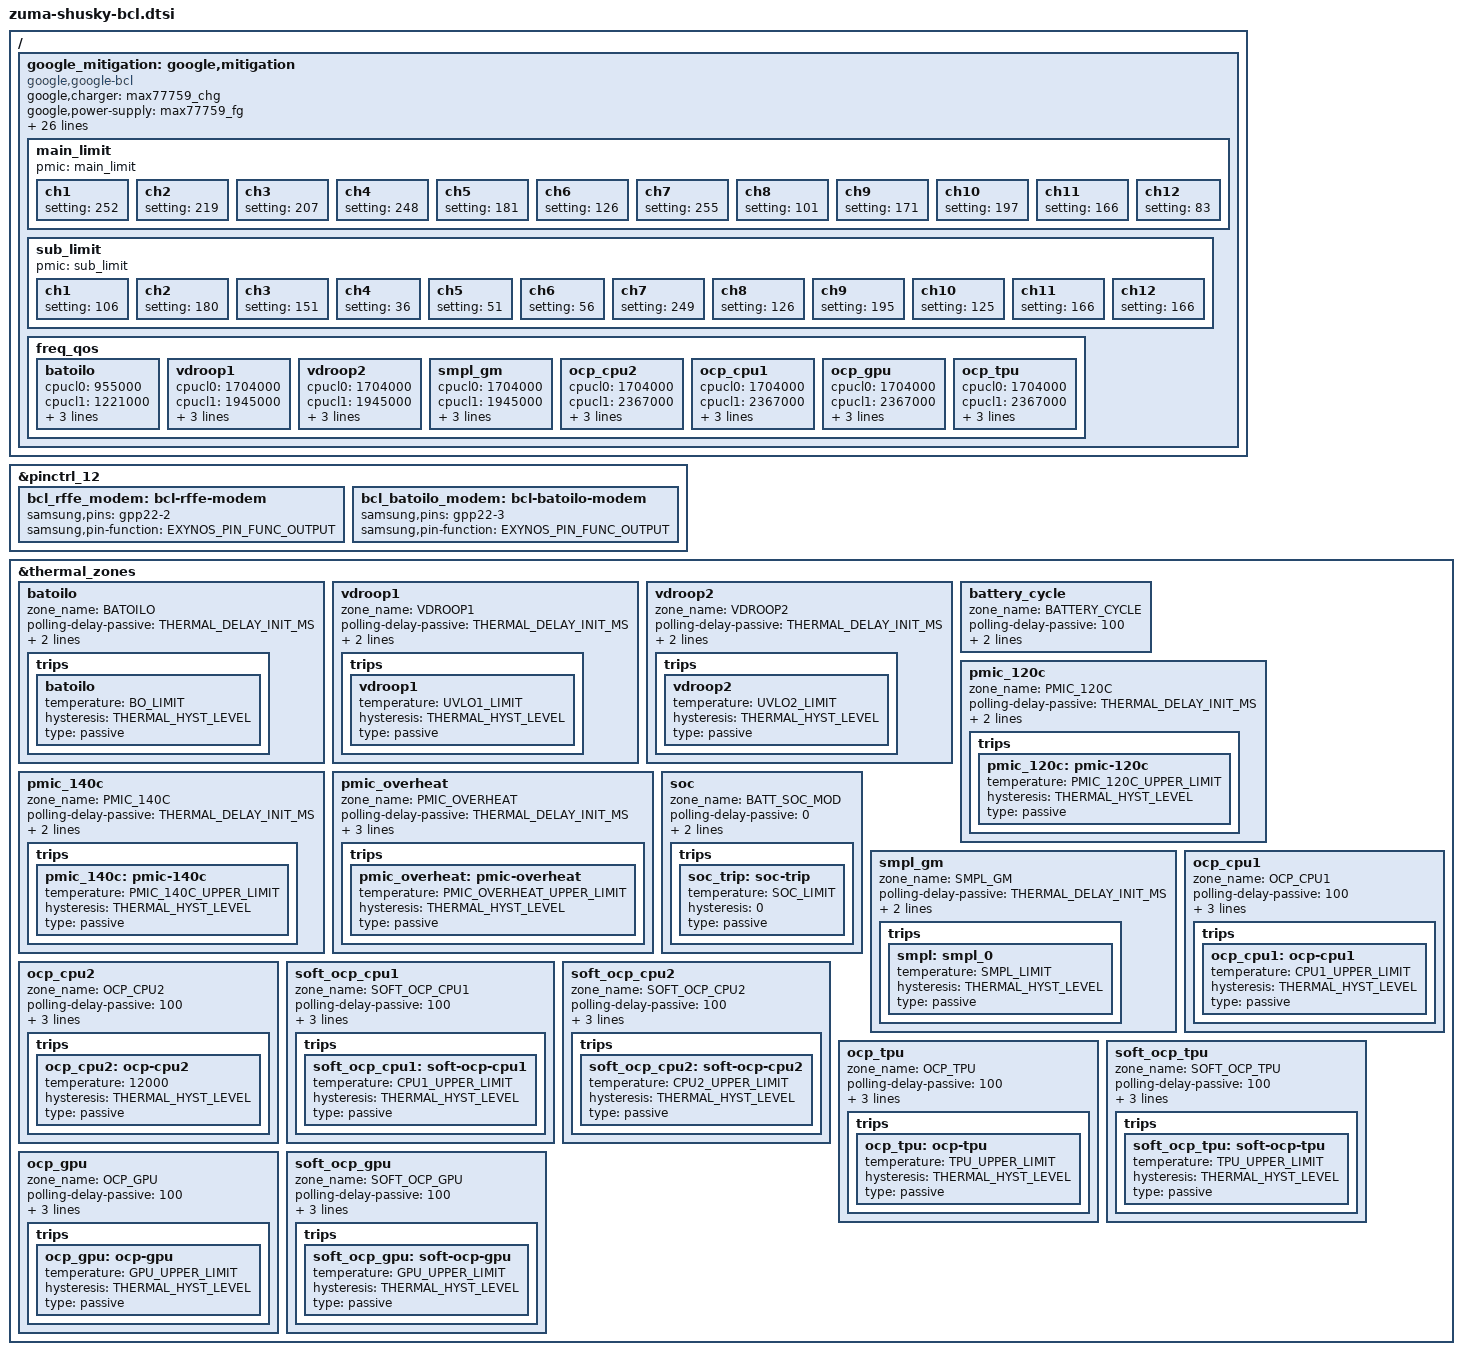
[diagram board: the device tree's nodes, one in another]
// SPDX-License-Identifier: GPL-2.0
/*
 * Google Zuma shusky-specific bcl device tree source
 *
 * Copyright (c) 2022 Google, LLC
 *		https://www.google.com
 */

#include <dt-bindings/thermal/thermal.h>
#include <dt-bindings/soc/google/zuma-bcl.h>

&pinctrl_12 {
	bcl_rffe_modem: bcl-rffe-modem {
		samsung,pins = "gpp22-2";
		samsung,pin-function = <EXYNOS_PIN_FUNC_OUTPUT>;
	};
	bcl_batoilo_modem: bcl-batoilo-modem {
		samsung,pins = "gpp22-3";
		samsung,pin-function = <EXYNOS_PIN_FUNC_OUTPUT>;
	};
};

/ {
	fragment@battery {
		target-path = "/";
		__overlay__ {
			google_mitigation: google,mitigation {
				compatible = "google,google-bcl";
				#thermal-sensor-cells = <1>;
				google,charger = <&max77759_chg>;
				google,power-supply = <&max77759_fg>;
				google,main-power = <&s2mpg14mfd>;
				google,sub-power = <&s2mpg15mfd>;
				ppm_settings = <0>;
				lit_mpmm_settings = <0x1AA>;
				mid_mpmm_settings = <0x1AA>;
				big_mpmm_settings = <0x6>;
				mpmm_en = <0x1f0>;
				tpu_con_heavy = <0xfff041c3>;
				tpu_con_light = <0xfff041c1>;
				tpu_clkdivstep = <0x1>;
				gpu_con_heavy = <0xfff04385>;
				gpu_con_light = <0xfff041c1>;
				gpu_clkdivstep = <0x1>;
				cpu2_clkdivstep = <0x1>;
				cpu1_clkdivstep = <0x1>;
				cpu0_clkdivstep = <0x1>;
				aur_clkdivstep = <0x1>;
				irq_enable_delay = <50>;
				odpm_ratio = <3>;
				gpios = <&gpa9 5 0>,		/* VDROOP1 */
					<&gpa9 6 0>,		/* VDROOP2 */
					<&gpp22 2 0>,		/* MODEM 1 */
					<&gpp22 3 0>;		/* MODEM 2 */
				rffe_channel = <11>;
				pinctrl-names = "bcl-rffe-modem", "bcl-batoilo-modem";
				pinctrl-0 = <&bcl_rffe_modem>;
				pinctrl-1 = <&bcl_batoilo_modem>;
				cpu0_cluster = <0>;
				cpu1_cluster = <4>;
				cpu2_cluster = <8>;

				main_limit {
					pmic = "main_limit";
					ch1 { setting = <252>; };
					ch2 { setting = <219>; };
					ch3 { setting = <207>; };
					ch4 { setting = <248>; };
					ch5 { setting = <181>; };
					ch6 { setting = <126>; };
					ch7 { setting = <255>; };
					ch8 { setting = <101>; };
					ch9 { setting = <171>; };
					ch10 { setting = <197>; };
					ch11 { setting = <166>; };
					ch12 { setting = <83>; };
				};
				sub_limit {
					pmic = "sub_limit";
					ch1 { setting = <106>; };
					ch2 { setting = <180>; };
					ch3 { setting = <151>; };
					ch4 { setting = <36>; };
					ch5 { setting = <51>; };
					ch6 { setting = <56>; };
					ch7 { setting = <249>; };
					ch8 { setting = <126>; };
					ch9 { setting = <195>; };
					ch10 { setting = <125>; };
					ch11 { setting = <166>; };
					ch12 { setting = <166>; };
				};
				freq_qos {
					batoilo {
						cpucl0 = <955000>;
						cpucl1 = <1221000>;
						cpucl2 = <1557000>;
						gpu = <723000>;
						tpu = <845000>;
					};
					vdroop1 {
						cpucl0 = <1704000>;
						cpucl1 = <1945000>;
						cpucl2 = <2294000>;
						gpu = <890000>;
						tpu = <845000>;
					};
					vdroop2 {
						cpucl0 = <1704000>;
						cpucl1 = <1945000>;
						cpucl2 = <2294000>;
						gpu = <649000>;
						tpu = <627000>;
					};
					smpl_gm {
						cpucl0 = <1704000>;
						cpucl1 = <1945000>;
						cpucl2 = <2294000>;
						gpu = <649000>;
						tpu = <627000>;
					};
					ocp_cpu2 {
						cpucl0 = <1704000>;
						cpucl1 = <2367000>;
						cpucl2 = <2914000>;
						gpu = <890000>;
						tpu = <1119000>;
					};
					ocp_cpu1 {
						cpucl0 = <1704000>;
						cpucl1 = <2367000>;
						cpucl2 = <2914000>;
						gpu = <890000>;
						tpu = <1119000>;
					};
					ocp_gpu {
						cpucl0 = <1704000>;
						cpucl1 = <2367000>;
						cpucl2 = <2914000>;
						gpu = <890000>;
						tpu = <1119000>;
					};
					ocp_tpu {
						cpucl0 = <1704000>;
						cpucl1 = <2367000>;
						cpucl2 = <2914000>;
						gpu = <890000>;
						tpu = <1119000>;
					};
				};
			};
		};
	};
};

/* Thermal Zones */
&thermal_zones {
	batoilo {
		zone_name  = "BATOILO";
		polling-delay-passive = <THERMAL_DELAY_INIT_MS>;
		polling-delay = <0>;
		thermal-sensors = <&google_mitigation BATOILO>;
		trips {
			batoilo: batoilo{
				temperature = <BO_LIMIT>;
				hysteresis = <THERMAL_HYST_LEVEL>;
				type = "passive";
			};
		};
	};

	vdroop1 {
		zone_name  = "VDROOP1";
		polling-delay-passive = <THERMAL_DELAY_INIT_MS>;
		polling-delay = <0>;
		thermal-sensors = <&google_mitigation UVLO1>;
		trips {
			vdroop1: vdroop1{
				temperature = <UVLO1_LIMIT>;
				hysteresis = <THERMAL_HYST_LEVEL>;
				type = "passive";
			};
		};
	};

	vdroop2 {
		zone_name  = "VDROOP2";
		polling-delay-passive = <THERMAL_DELAY_INIT_MS>;
		polling-delay = <0>;
		thermal-sensors = <&google_mitigation UVLO2>;
		trips {
			vdroop2: vdroop2{
				temperature = <UVLO2_LIMIT>;
				hysteresis = <THERMAL_HYST_LEVEL>;
				type = "passive";
			};
		};
	};

	battery_cycle {
		zone_name  = "BATTERY_CYCLE";
		polling-delay-passive = <100>;
		polling-delay = <0>;
		thermal-sensors = <&google_battery>;
	};

	pmic_120c {
		zone_name  = "PMIC_120C";
		polling-delay-passive = <THERMAL_DELAY_INIT_MS>;
		polling-delay = <0>;
		thermal-sensors = <&google_mitigation PMIC_120C>;
		trips {
			pmic_120c: pmic-120c {
				temperature = <PMIC_120C_UPPER_LIMIT>;
				hysteresis = <THERMAL_HYST_LEVEL>;
				type = "passive";
			};
		};
	};

	pmic_140c {
		zone_name  = "PMIC_140C";
		polling-delay-passive = <THERMAL_DELAY_INIT_MS>;
		polling-delay = <0>;
		thermal-sensors = <&google_mitigation PMIC_140C>;
		trips {
			pmic_140c: pmic-140c {
				temperature = <PMIC_140C_UPPER_LIMIT>;
				hysteresis = <THERMAL_HYST_LEVEL>;
				type = "passive";
			};
		};
	};

	pmic_overheat {
		zone_name  = "PMIC_OVERHEAT";
		polling-delay-passive = <THERMAL_DELAY_INIT_MS>;
		polling-delay = <0>;
		thermal-sensors = <&google_mitigation PMIC_OVERHEAT>;
		trips {
			pmic_overheat: pmic-overheat{
				temperature = <PMIC_OVERHEAT_UPPER_LIMIT>;
				hysteresis = <THERMAL_HYST_LEVEL>;
				type = "passive";
			};
		};
	};

	soc {
		zone_name  = "BATT_SOC_MOD";
		polling-delay-passive = <0>;
		polling-delay = <0>;
		thermal-sensors = <&google_mitigation PMIC_SOC>;

		trips {
			soc_trip:soc-trip {
				temperature = <SOC_LIMIT>;
				hysteresis = <0>;
				type = "passive";
			};
		};
	};

	smpl_gm {
		zone_name  = "SMPL_GM";
		polling-delay-passive = <THERMAL_DELAY_INIT_MS>;
		polling-delay = <0>;
		thermal-sensors = <&google_mitigation SMPL_WARN>;

		trips {
			smpl:smpl_0 {
				temperature = <SMPL_LIMIT>;
				hysteresis = <THERMAL_HYST_LEVEL>;
				type = "passive";
			};
		};
	};
	ocp_cpu1 {
		zone_name  = "OCP_CPU1";
		polling-delay-passive = <100>;
		polling-delay = <0>;
		thermal-sensors = <&google_mitigation OCP_WARN_CPUCL1>;

		trips {
			ocp_cpu1:ocp-cpu1 {
				temperature = <CPU1_UPPER_LIMIT>;
				hysteresis = <THERMAL_HYST_LEVEL>;
				type = "passive";
			};
		};
	};
	ocp_cpu2 {
		zone_name  = "OCP_CPU2";
		polling-delay-passive = <100>;
		polling-delay = <0>;
		thermal-sensors = <&google_mitigation OCP_WARN_CPUCL2>;

		trips {
			ocp_cpu2:ocp-cpu2 {
				temperature = <12000>;
				hysteresis = <THERMAL_HYST_LEVEL>;
				type = "passive";
			};
		};
	};
	soft_ocp_cpu1 {
		zone_name  = "SOFT_OCP_CPU1";
		polling-delay-passive = <100>;
		polling-delay = <0>;
		thermal-sensors = <&google_mitigation SOFT_OCP_WARN_CPUCL1>;

		trips {
			soft_ocp_cpu1:soft-ocp-cpu1 {
				temperature = <CPU1_UPPER_LIMIT>;
				hysteresis = <THERMAL_HYST_LEVEL>;
				type = "passive";
			};
		};
	};
	soft_ocp_cpu2 {
		zone_name  = "SOFT_OCP_CPU2";
		polling-delay-passive = <100>;
		polling-delay = <0>;
		thermal-sensors = <&google_mitigation SOFT_OCP_WARN_CPUCL2>;

		trips {
			soft_ocp_cpu2:soft-ocp-cpu2 {
				temperature = <CPU2_UPPER_LIMIT>;
				hysteresis = <THERMAL_HYST_LEVEL>;
				type = "passive";
			};
		};
	};
	ocp_tpu {
		zone_name  = "OCP_TPU";
		polling-delay-passive = <100>;
		polling-delay = <0>;
		thermal-sensors = <&google_mitigation OCP_WARN_TPU>;

		trips {
			ocp_tpu:ocp-tpu{
				temperature = <TPU_UPPER_LIMIT>;
				hysteresis = <THERMAL_HYST_LEVEL>;
				type = "passive";
			};
		};
	};
	soft_ocp_tpu {
		zone_name  = "SOFT_OCP_TPU";
		polling-delay-passive = <100>;
		polling-delay = <0>;
		thermal-sensors = <&google_mitigation SOFT_OCP_WARN_TPU>;

		trips {
			soft_ocp_tpu:soft-ocp-tpu {
				temperature = <TPU_UPPER_LIMIT>;
				hysteresis = <THERMAL_HYST_LEVEL>;
				type = "passive";
			};
		};
	};
	ocp_gpu {
		zone_name  = "OCP_GPU";
		polling-delay-passive = <100>;
		polling-delay = <0>;
		thermal-sensors = <&google_mitigation OCP_WARN_GPU>;

		trips {
			ocp_gpu:ocp-gpu{
				temperature = <GPU_UPPER_LIMIT>;
				hysteresis = <THERMAL_HYST_LEVEL>;
				type = "passive";
			};
		};
	};
	soft_ocp_gpu {
		zone_name  = "SOFT_OCP_GPU";
		polling-delay-passive = <100>;
		polling-delay = <0>;
		thermal-sensors = <&google_mitigation SOFT_OCP_WARN_GPU>;

		trips {
			soft_ocp_gpu:soft-ocp-gpu {
				temperature = <GPU_UPPER_LIMIT>;
				hysteresis = <THERMAL_HYST_LEVEL>;
				type = "passive";
			};
		};
	};
};
